AUTOSAR XML (schema 4-0-3)
standard types defined: Boolean, UInt32
package /AUTOSAR_Platform/DataConstrs
  range DC_Boolean: raw 0..1
package /PATAC/MSM/ComponentTypes
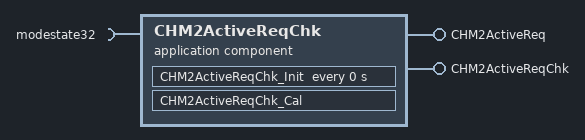
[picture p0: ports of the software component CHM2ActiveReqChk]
  application sw component type CHM2ActiveReqChk
    provide port CHM2ActiveReq: nonqueued-sender-com-spec{data-element=CHM2ActiveReq/Val, init-value=0}, provided-interface=CHM2ActiveReq
    provide port CHM2ActiveReqChk: server-com-spec{operation=Cal, queue-length=1}, provided-interface=CHM2ActiveReqChk
    require port modestate32: nonqueued-receiver-com-spec{data-element=modestate32/Val, filter=data-filter-type=ALWAYS, init-value=0}, required-interface=modestate32
    behavior CHM2ActiveReqChk_InternalBehavior
      operation invoked event OIT_CHM2ActiveReqChk_Cal_CHM2ActiveReqChk_Cal: start-on-event=CHM2ActiveReqChk_Cal, operation=CHM2ActiveReqChk.Cal
      timing event CHM2ActiveReqChk_InitEvent: start-on-event=CHM2ActiveReqChk_Init, period=0
      runnable CHM2ActiveReqChk_Cal
        data-receive-point-by-arguments:
          access REC_modestate32_Val: accessed-variable=modestate32.Val
        data-send-points:
          access SEND_CHM2ActiveReq_Val: accessed-variable=CHM2ActiveReq.Val
      runnable CHM2ActiveReqChk_Init
  swc implementation CHM2ActiveReqChk_Implementation: behavior=CHM2ActiveReqChk_InternalBehavior
    code-descriptors:
      code Default: artifact-descriptors=autosar-engineering-object={short-label=Default, category=SWSRC}
package /PATAC/MSM/ModeAdjust/PortInterface
  client server interface CHM2ActiveReqChk
    operation Cal
  sender receiver interface CHM2ActiveReq: invalidation-policy{data-element=CHM2ActiveReq/Val, handle-invalid=DONT-INVALIDATE}
    data Val: type=Boolean
  sender receiver interface modestate32: invalidation-policy{data-element=modestate32/Val, handle-invalid=DONT-INVALIDATE}
    data Val: type=UInt32
